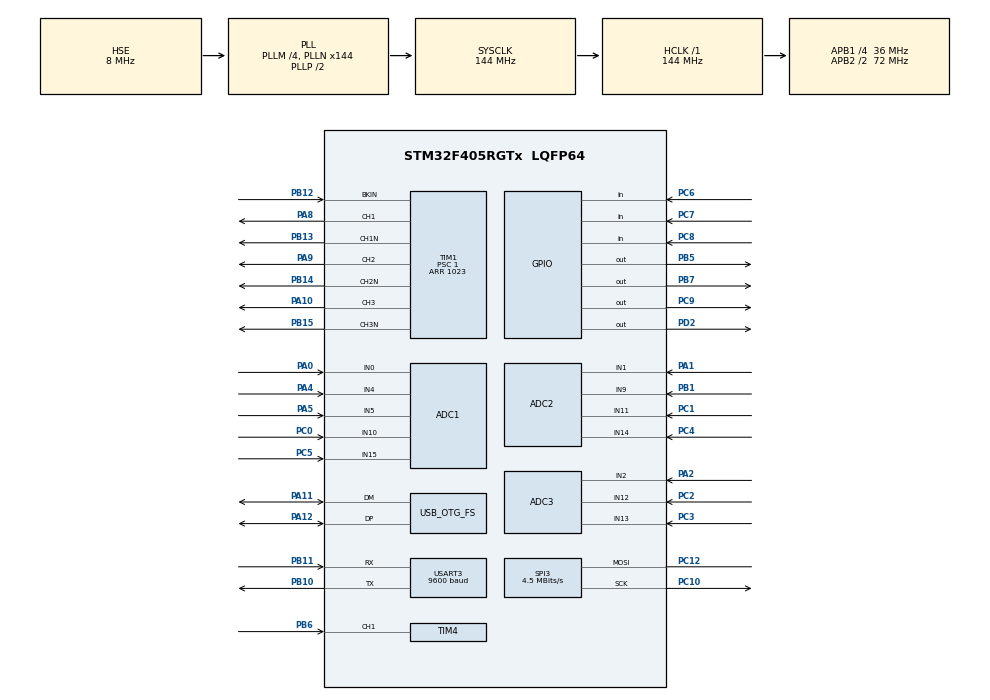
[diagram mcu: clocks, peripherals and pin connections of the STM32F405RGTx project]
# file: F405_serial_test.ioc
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ADC1.Channel-0\#ChannelRegularConversion=ADC_CHANNEL_10
ADC1.Channel-1\#ChannelInjectedConversion=ADC_CHANNEL_10
ADC1.Channel-2\#ChannelInjectedConversion=ADC_CHANNEL_0
ADC1.Channel-3\#ChannelInjectedConversion=ADC_CHANNEL_5
ADC1.Channel-4\#ChannelInjectedConversion=ADC_CHANNEL_4
ADC1.EOCSelection=ADC_EOC_SEQ_CONV
ADC1.EnableAnalogWatchDog=false
ADC1.ExternalTrigInjecConv=ADC_EXTERNALTRIGINJECCONV_T1_TRGO
ADC1.InjNumberOfConversion=4
ADC1.InjectedOffset-1\#ChannelInjectedConversion=0
ADC1.InjectedOffset-2\#ChannelInjectedConversion=0
ADC1.InjectedOffset-3\#ChannelInjectedConversion=0
ADC1.InjectedOffset-4\#ChannelInjectedConversion=0
ADC1.InjectedRank-1\#ChannelInjectedConversion=1
ADC1.InjectedRank-2\#ChannelInjectedConversion=2
ADC1.InjectedRank-3\#ChannelInjectedConversion=3
ADC1.InjectedRank-4\#ChannelInjectedConversion=4
ADC1.NbrOfConversion=1
ADC1.NbrOfConversionFlag=1
ADC1.Rank-0\#ChannelRegularConversion=1
ADC1.SamplingTime-0\#ChannelRegularConversion=ADC_SAMPLETIME_3CYCLES
ADC1.SamplingTime-1\#ChannelInjectedConversion=ADC_SAMPLETIME_15CYCLES
ADC1.SamplingTime-2\#ChannelInjectedConversion=ADC_SAMPLETIME_15CYCLES
ADC1.SamplingTime-3\#ChannelInjectedConversion=ADC_SAMPLETIME_15CYCLES
ADC1.SamplingTime-4\#ChannelInjectedConversion=ADC_SAMPLETIME_3CYCLES
ADC1.ScanConvMode=ENABLE
ADC1.master=1
ADC2.Channel-0\#ChannelRegularConversion=ADC_CHANNEL_11
ADC2.Channel-1\#ChannelInjectedConversion=ADC_CHANNEL_11
ADC2.Channel-2\#ChannelInjectedConversion=ADC_CHANNEL_14
ADC2.Channel-3\#ChannelInjectedConversion=ADC_CHANNEL_1
ADC2.Channel-4\#ChannelInjectedConversion=ADC_CHANNEL_9
ADC2.EOCSelection=ADC_EOC_SEQ_CONV
ADC2.ExternalTrigInjecConv=ADC_EXTERNALTRIGINJECCONV_T1_TRGO
ADC2.InjNumberOfConversion=4
ADC2.InjectedOffset-1\#ChannelInjectedConversion=0
ADC2.InjectedOffset-2\#ChannelInjectedConversion=0
ADC2.InjectedOffset-3\#ChannelInjectedConversion=0
ADC2.InjectedOffset-4\#ChannelInjectedConversion=0
ADC2.InjectedRank-1\#ChannelInjectedConversion=1
ADC2.InjectedRank-2\#ChannelInjectedConversion=2
ADC2.InjectedRank-3\#ChannelInjectedConversion=3
ADC2.InjectedRank-4\#ChannelInjectedConversion=4
ADC2.NbrOfConversionFlag=1
ADC2.Rank-0\#ChannelRegularConversion=1
ADC2.SamplingTime-0\#ChannelRegularConversion=ADC_SAMPLETIME_3CYCLES
ADC2.SamplingTime-1\#ChannelInjectedConversion=ADC_SAMPLETIME_15CYCLES
ADC2.SamplingTime-2\#ChannelInjectedConversion=ADC_SAMPLETIME_15CYCLES
ADC2.SamplingTime-3\#ChannelInjectedConversion=ADC_SAMPLETIME_15CYCLES
ADC2.SamplingTime-4\#ChannelInjectedConversion=ADC_SAMPLETIME_15CYCLES
ADC3.Channel-0\#ChannelRegularConversion=ADC_CHANNEL_12
ADC3.Channel-1\#ChannelInjectedConversion=ADC_CHANNEL_12
ADC3.Channel-2\#ChannelInjectedConversion=ADC_CHANNEL_13
ADC3.Channel-3\#ChannelInjectedConversion=ADC_CHANNEL_2
ADC3.EOCSelection=ADC_EOC_SEQ_CONV
ADC3.ExternalTrigInjecConv=ADC_EXTERNALTRIGINJECCONV_T1_TRGO
ADC3.InjNumberOfConversion=3
ADC3.InjectedOffset-1\#ChannelInjectedConversion=0
ADC3.InjectedOffset-2\#ChannelInjectedConversion=0
ADC3.InjectedOffset-3\#ChannelInjectedConversion=0
ADC3.InjectedRank-1\#ChannelInjectedConversion=1
ADC3.InjectedRank-2\#ChannelInjectedConversion=2
ADC3.InjectedRank-3\#ChannelInjectedConversion=3
ADC3.NbrOfConversionFlag=1
ADC3.Rank-0\#ChannelRegularConversion=1
ADC3.SamplingTime-0\#ChannelRegularConversion=ADC_SAMPLETIME_3CYCLES
ADC3.SamplingTime-1\#ChannelInjectedConversion=ADC_SAMPLETIME_15CYCLES
ADC3.SamplingTime-2\#ChannelInjectedConversion=ADC_SAMPLETIME_15CYCLES
ADC3.SamplingTime-3\#ChannelInjectedConversion=ADC_SAMPLETIME_15CYCLES
Dma.Request0=USART3_TX
Dma.USART3_TX.0.Direction=DMA_MEMORY_TO_PERIPH
Dma.USART3_TX.0.FIFOMode=DMA_FIFOMODE_DISABLE
Dma.USART3_TX.0.Instance=DMA1_Stream3
Dma.USART3_TX.0.MemDataAlignment=DMA_MDATAALIGN_BYTE
Dma.USART3_TX.0.MemInc=DMA_MINC_ENABLE
Dma.USART3_TX.0.Mode=DMA_NORMAL
Dma.USART3_TX.0.PeriphDataAlignment=DMA_PDATAALIGN_BYTE
Dma.USART3_TX.0.PeriphInc=DMA_PINC_DISABLE
Dma.USART3_TX.0.Priority=DMA_PRIORITY_LOW
Mcu.Family=STM32F4
Mcu.Name=STM32F405RGTx
Mcu.Package=LQFP64
NVIC.ADC_IRQn=true\:0\:0\:false\:false\:true\:true\:false\:true
NVIC.DMA1_Stream3_IRQn=true\:1\:0\:true\:false\:true\:false\:true\:true
NVIC.OTG_FS_IRQn=true\:3\:0\:true\:false\:true\:true\:true\:true
NVIC.PriorityGroup=NVIC_PRIORITYGROUP_4
NVIC.TIM1_UP_TIM10_IRQn=true\:1\:0\:true\:false\:true\:true\:false\:true
NVIC.TIM4_IRQn=true\:2\:0\:true\:false\:true\:true\:false\:true
NVIC.USART3_IRQn=true\:2\:0\:true\:false\:true\:true\:true\:true
PA0-WKUP.Signal=ADCx_IN0
PA1.Signal=ADCx_IN1
PA10.Signal=S_TIM1_CH3
PA11.Mode=Device_Only
PA11.Signal=USB_OTG_FS_DM
PA12.Mode=Device_Only
PA12.Signal=USB_OTG_FS_DP
PA13.Mode=Trace_Asynchronous_SW
PA13.Signal=SYS_JTMS-SWDIO
PA14.Mode=Trace_Asynchronous_SW
PA14.Signal=SYS_JTCK-SWCLK
PA2.Signal=ADCx_IN2
PA4.Signal=ADCx_IN4
PA5.Signal=ADCx_IN5
PA8.Signal=S_TIM1_CH1
PA9.Signal=S_TIM1_CH2
PB1.Signal=ADCx_IN9
PB10.Signal=SharedStack_PB10
PB10.Stacked=true
PB11.Signal=SharedStack_PB11
PB11.Stacked=true
PB12.Mode=Activate-Break-Input
PB12.Signal=TIM1_BKIN
PB13.Mode=PWM Generation1 CH1 CH1N
PB13.Signal=TIM1_CH1N
PB14.Mode=PWM Generation2 CH2 CH2N
PB14.Signal=TIM1_CH2N
PB15.Mode=PWM Generation3 CH3 CH3N
PB15.Signal=TIM1_CH3N
PB3.Mode=Trace_Asynchronous_SW
PB3.Signal=SYS_JTDO-SWO
PB5.Signal=GPIO_Output
PB6.Signal=S_TIM4_CH1
PB7.Signal=GPIO_Output
PC0.Signal=ADCx_IN10
PC1.Signal=ADCx_IN11
PC10.Mode=Simplex_Bidirectional_Master
PC10.Signal=SPI3_SCK
PC11.Signal=SPI3_MISO
PC12.Mode=Simplex_Bidirectional_Master
PC12.Signal=SPI3_MOSI
PC2.Signal=ADCx_IN12
PC3.Signal=ADCx_IN13
PC4.Signal=ADCx_IN14
PC5.Signal=ADCx_IN15
PC6.Signal=GPIO_Input
PC7.Signal=GPIO_Input
PC8.Signal=GPIO_Input
PC9.Signal=GPIO_Output
PD2.Signal=GPIO_Output
PH0-OSC_IN.Mode=HSE-External-Oscillator
PH0-OSC_IN.Signal=RCC_OSC_IN
PH1-OSC_OUT.Mode=HSE-External-Oscillator
PH1-OSC_OUT.Signal=RCC_OSC_OUT
ProjectManager.HeapSize=0x200
ProjectManager.StackSize=0x400
ProjectManager.TargetToolchain=STM32CubeIDE
RCC.48MHZClocksFreq_Value=48000000
RCC.AHBFreq_Value=144000000
RCC.APB1CLKDivider=RCC_HCLK_DIV4
RCC.APB1Freq_Value=36000000
RCC.APB1TimFreq_Value=72000000
RCC.APB2CLKDivider=RCC_HCLK_DIV2
RCC.APB2Freq_Value=72000000
RCC.APB2TimFreq_Value=144000000
RCC.CortexFreq_Value=144000000
RCC.HCLKFreq_Value=144000000
RCC.HSE_VALUE=8000000
RCC.HSI_VALUE=16000000
RCC.LSE_VALUE=32768
RCC.PLLM=4
RCC.PLLN=144
RCC.PLLQ=6
RCC.SYSCLKFreq_VALUE=144000000
RCC.SYSCLKSource=RCC_SYSCLKSOURCE_PLLCLK
RCC.VCOOutputFreq_Value=288000000
SH.ADCx_IN0.0=ADC1_IN0,IN0
SH.ADCx_IN1.0=ADC2_IN1,IN1
SH.ADCx_IN10.0=ADC1_IN10,IN10
SH.ADCx_IN11.0=ADC2_IN11,IN11
SH.ADCx_IN12.0=ADC3_IN12,IN12
SH.ADCx_IN13.0=ADC3_IN13,IN13
SH.ADCx_IN14.0=ADC2_IN14,IN14
SH.ADCx_IN15.0=ADC1_IN15,IN15
SH.ADCx_IN2.0=ADC3_IN2,IN2
SH.ADCx_IN4.0=ADC1_IN4,IN4
SH.ADCx_IN5.0=ADC1_IN5,IN5
SH.ADCx_IN9.0=ADC2_IN9,IN9
SH.S_TIM1_CH1.0=TIM1_CH1,PWM Generation1 CH1 CH1N
SH.S_TIM1_CH2.0=TIM1_CH2,PWM Generation2 CH2 CH2N
SH.S_TIM1_CH3.0=TIM1_CH3,PWM Generation3 CH3 CH3N
SH.S_TIM4_CH1.0=TIM4_CH1,Input_Capture1_from_TI1
SH.S_TIM4_CH1.1=TIM4_CH1,Input_Capture2_from_TI1
SH.S_TIM4_CH1.2=TIM4_CH1,TriggerSource_TI1FP1
SH.SharedStack_PB10.0=USART3_TX,Asynchronous
SH.SharedStack_PB10.1=I2C2_SCL
SH.SharedStack_PB11.0=USART3_RX,Asynchronous
SH.SharedStack_PB11.1=I2C2_SDA
SPI3.BaudRatePrescaler=SPI_BAUDRATEPRESCALER_8
SPI3.CLKPhase=SPI_PHASE_2EDGE
SPI3.CalculateBaudRate=4.5 MBits/s
SPI3.DataSize=SPI_DATASIZE_16BIT
SPI3.Direction=SPI_DIRECTION_1LINE
SPI3.Mode=SPI_MODE_MASTER
SPI3.VirtualType=VM_MASTER
TIM1.BreakPolarity=TIM_BREAKPOLARITY_LOW
TIM1.Channel-PWM\ Generation1\ CH1\ CH1N=TIM_CHANNEL_1
TIM1.Channel-PWM\ Generation2\ CH2\ CH2N=TIM_CHANNEL_2
TIM1.Channel-PWM\ Generation3\ CH3\ CH3N=TIM_CHANNEL_3
TIM1.Channel-PWM\ Generation4\ No\ Output=TIM_CHANNEL_4
TIM1.CounterMode=TIM_COUNTERMODE_CENTERALIGNED1
TIM1.DeadTime=50
TIM1.OffStateIDLEMode=TIM_OSSI_ENABLE
TIM1.OffStateRunMode=TIM_OSSR_ENABLE
TIM1.Period=1023
TIM1.Prescaler=1
TIM1.Pulse-PWM\ Generation1\ CH1\ CH1N=512
TIM1.Pulse-PWM\ Generation2\ CH2\ CH2N=512
TIM1.Pulse-PWM\ Generation3\ CH3\ CH3N=512
TIM1.TIM_MasterOutputTrigger=TIM_TRGO_OC4REF
TIM4.Channel-Input_Capture1_from_TI1=TIM_CHANNEL_1
TIM4.Channel-Input_Capture2_from_TI1=TIM_CHANNEL_2
TIM4.ICPolarity_CH2=TIM_INPUTCHANNELPOLARITY_FALLING
TIM4.Period=50000
TIM4.Prescaler=71
USART3.BaudRate=9600
USART3.VirtualMode=VM_ASYNC
USB_DEVICE.APP_RX_DATA_SIZE-CDC_FS=1000
USB_DEVICE.APP_TX_DATA_SIZE-CDC_FS=1000
USB_DEVICE.CLASS_NAME_FS=CDC
USB_DEVICE.VirtualMode-CDC_FS=Cdc
USB_DEVICE.VirtualModeFS=Cdc_FS
USB_OTG_FS.VirtualMode=Device_Only
VP_TIM1_VS_no_output4.Mode=PWM Generation4 No Output
VP_TIM4_VS_ControllerModeReset.Mode=Reset Mode
VP_TIM7_VS_ClockSourceINT.Mode=Enable_Timer
VP_USB_DEVICE_VS_USB_DEVICE_CDC_FS.Mode=CDC_FS
board=custom

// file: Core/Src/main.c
/* USER CODE BEGIN Header */
/**
  ******************************************************************************
  * @file           : main.c
  * @brief          : Main program body
  ******************************************************************************
  * @attention
  *
  * Copyright (c) 2022 STMicroelectronics.
  * All rights reserved.
  *
  * This software is licensed under terms that can be found in the LICENSE file
  * in the root directory of this software component.
  * If no LICENSE file comes with this software, it is provided AS-IS.
  *
  ******************************************************************************
  */
/* USER CODE END Header */
#include "main.h"
#include "usb_device.h"
#include <stdbool.h>

ADC_HandleTypeDef hadc1;
ADC_HandleTypeDef hadc2;
ADC_HandleTypeDef hadc3;

SPI_HandleTypeDef hspi3;

TIM_HandleTypeDef htim1;
TIM_HandleTypeDef htim4;
TIM_HandleTypeDef htim7;

UART_HandleTypeDef huart3;
DMA_HandleTypeDef hdma_usart3_tx;

void SystemClock_Config(void);
static void MX_GPIO_Init(void);
static void MX_DMA_Init(void);
static void MX_ADC1_Init(void);
static void MX_ADC2_Init(void);
static void MX_ADC3_Init(void);
static void MX_TIM1_Init(void);
static void MX_TIM4_Init(void);
static void MX_USART3_UART_Init(void);
static void MX_TIM7_Init(void);
static void MX_SPI3_Init(void);

/* USER CODE BEGIN 0 */
uint32_t milliStart;
uint32_t milliCurrent;
uint32_t milliDelta;
bool milliReset = true;

/* USER CODE END 0 */

int main(void)
{

  /* MCU Configuration--------------------------------------------------------*/

  /* Reset of all peripherals, Initializes the Flash interface and the Systick. */
  HAL_Init();

  /* Configure the system clock */
  SystemClock_Config();

  /* Initialize all configured peripherals */
  MX_GPIO_Init();
  MX_DMA_Init();
  MX_ADC1_Init();
  MX_ADC2_Init();
  MX_ADC3_Init();
  MX_TIM1_Init();
  MX_TIM4_Init();
  MX_USART3_UART_Init();
  MX_TIM7_Init();
  MX_SPI3_Init();
  MX_USB_DEVICE_Init();

  /* Infinite loop */
  while (1)
  {
	  HAL_GPIO_TogglePin (GPIOC, GPIO_PIN_9);
	  HAL_Delay (120);
	  char transmit_buffer[100];
	  int sizebuff;
	  milliCurrent = HAL_GetTick();
	  if (milliReset) {
		  // some day it would be cool if the user could reset this
		  // doesnt work yet
		  milliStart = milliCurrent;
	  }
	  milliReset = false;

	  sizebuff = sprintf(transmit_buffer,"{\"mS\":%lu, \"amps\":%d, \"volts\":%d}\r\n", (milliCurrent - milliStart), rand() %  200, rand() % 200);
	  HAL_UART_Transmit_DMA(&huart3, transmit_buffer, sizebuff);
  }
}

void SystemClock_Config(void)
{
  RCC_OscInitTypeDef RCC_OscInitStruct = {0};
  RCC_ClkInitTypeDef RCC_ClkInitStruct = {0};

  /** Configure the main internal regulator output voltage
  */
  __HAL_RCC_PWR_CLK_ENABLE();
  __HAL_PWR_VOLTAGESCALING_CONFIG(PWR_REGULATOR_VOLTAGE_SCALE1);

  /** Initializes the RCC Oscillators according to the specified parameters
  * in the RCC_OscInitTypeDef structure.
  */
  RCC_OscInitStruct.OscillatorType = RCC_OSCILLATORTYPE_HSE;
  RCC_OscInitStruct.HSEState = RCC_HSE_ON;
  RCC_OscInitStruct.PLL.PLLState = RCC_PLL_ON;
  RCC_OscInitStruct.PLL.PLLSource = RCC_PLLSOURCE_HSE;
  RCC_OscInitStruct.PLL.PLLM = 4;
  RCC_OscInitStruct.PLL.PLLN = 144;
  RCC_OscInitStruct.PLL.PLLP = RCC_PLLP_DIV2;
  RCC_OscInitStruct.PLL.PLLQ = 6;
  if (HAL_RCC_OscConfig(&RCC_OscInitStruct) != HAL_OK)
  {
    Error_Handler();
  }

  /** Initializes the CPU, AHB and APB buses clocks
  */
  RCC_ClkInitStruct.ClockType = RCC_CLOCKTYPE_HCLK|RCC_CLOCKTYPE_SYSCLK
                              |RCC_CLOCKTYPE_PCLK1|RCC_CLOCKTYPE_PCLK2;
  RCC_ClkInitStruct.SYSCLKSource = RCC_SYSCLKSOURCE_PLLCLK;
  RCC_ClkInitStruct.AHBCLKDivider = RCC_SYSCLK_DIV1;
  RCC_ClkInitStruct.APB1CLKDivider = RCC_HCLK_DIV4;
  RCC_ClkInitStruct.APB2CLKDivider = RCC_HCLK_DIV2;

  if (HAL_RCC_ClockConfig(&RCC_ClkInitStruct, FLASH_LATENCY_4) != HAL_OK)
  {
    Error_Handler();
  }
}

static void MX_ADC1_Init(void)
{

  ADC_ChannelConfTypeDef sConfig = {0};
  ADC_InjectionConfTypeDef sConfigInjected = {0};

  /** Configure the global features of the ADC (Clock, Resolution, Data Alignment and number of conversion)
  */
  hadc1.Instance = ADC1;
  hadc1.Init.ClockPrescaler = ADC_CLOCK_SYNC_PCLK_DIV2;
  hadc1.Init.Resolution = ADC_RESOLUTION_12B;
  hadc1.Init.ScanConvMode = ENABLE;
  hadc1.Init.ContinuousConvMode = DISABLE;
  hadc1.Init.DiscontinuousConvMode = DISABLE;
  hadc1.Init.ExternalTrigConvEdge = ADC_EXTERNALTRIGCONVEDGE_NONE;
  hadc1.Init.ExternalTrigConv = ADC_SOFTWARE_START;
  hadc1.Init.DataAlign = ADC_DATAALIGN_RIGHT;
  hadc1.Init.NbrOfConversion = 1;
  hadc1.Init.DMAContinuousRequests = DISABLE;
  hadc1.Init.EOCSelection = ADC_EOC_SEQ_CONV;
  if (HAL_ADC_Init(&hadc1) != HAL_OK)
  {
    Error_Handler();
  }

  /** Configure for the selected ADC regular channel its corresponding rank in the sequencer and its sample time.
  */
  sConfig.Channel = ADC_CHANNEL_10;
  sConfig.Rank = 1;
  sConfig.SamplingTime = ADC_SAMPLETIME_3CYCLES;
  if (HAL_ADC_ConfigChannel(&hadc1, &sConfig) != HAL_OK)
  {
    Error_Handler();
  }

  /** Configures for the selected ADC injected channel its corresponding rank in the sequencer and its sample time
  */
  sConfigInjected.InjectedChannel = ADC_CHANNEL_10;
  sConfigInjected.InjectedRank = 1;
  sConfigInjected.InjectedNbrOfConversion = 4;
  sConfigInjected.InjectedSamplingTime = ADC_SAMPLETIME_15CYCLES;
  sConfigInjected.ExternalTrigInjecConvEdge = ADC_EXTERNALTRIGINJECCONVEDGE_RISING;
  sConfigInjected.ExternalTrigInjecConv = ADC_EXTERNALTRIGINJECCONV_T1_TRGO;
  sConfigInjected.AutoInjectedConv = DISABLE;
  sConfigInjected.InjectedDiscontinuousConvMode = DISABLE;
  sConfigInjected.InjectedOffset = 0;
  if (HAL_ADCEx_InjectedConfigChannel(&hadc1, &sConfigInjected) != HAL_OK)
  {
    Error_Handler();
  }

  /** Configures for the selected ADC injected channel its corresponding rank in the sequencer and its sample time
  */
  sConfigInjected.InjectedChannel = ADC_CHANNEL_0;
  sConfigInjected.InjectedRank = 2;
  if (HAL_ADCEx_InjectedConfigChannel(&hadc1, &sConfigInjected) != HAL_OK)
  {
    Error_Handler();
  }

  /** Configures for the selected ADC injected channel its corresponding rank in the sequencer and its sample time
  */
  sConfigInjected.InjectedChannel = ADC_CHANNEL_5;
  sConfigInjected.InjectedRank = 3;
  if (HAL_ADCEx_InjectedConfigChannel(&hadc1, &sConfigInjected) != HAL_OK)
  {
    Error_Handler();
  }

  /** Configures for the selected ADC injected channel its corresponding rank in the sequencer and its sample time
  */
  sConfigInjected.InjectedChannel = ADC_CHANNEL_4;
  sConfigInjected.InjectedRank = 4;
  sConfigInjected.InjectedSamplingTime = ADC_SAMPLETIME_3CYCLES;
  if (HAL_ADCEx_InjectedConfigChannel(&hadc1, &sConfigInjected) != HAL_OK)
  {
    Error_Handler();
  }

}

static void MX_ADC2_Init(void)
{

  ADC_ChannelConfTypeDef sConfig = {0};
  ADC_InjectionConfTypeDef sConfigInjected = {0};

  /** Configure the global features of the ADC (Clock, Resolution, Data Alignment and number of conversion)
  */
  hadc2.Instance = ADC2;
  hadc2.Init.ClockPrescaler = ADC_CLOCK_SYNC_PCLK_DIV2;
  hadc2.Init.Resolution = ADC_RESOLUTION_12B;
  hadc2.Init.ScanConvMode = ENABLE;
  hadc2.Init.ContinuousConvMode = DISABLE;
  hadc2.Init.DiscontinuousConvMode = DISABLE;
  hadc2.Init.ExternalTrigConvEdge = ADC_EXTERNALTRIGCONVEDGE_NONE;
  hadc2.Init.ExternalTrigConv = ADC_SOFTWARE_START;
  hadc2.Init.DataAlign = ADC_DATAALIGN_RIGHT;
  hadc2.Init.NbrOfConversion = 1;
  hadc2.Init.DMAContinuousRequests = DISABLE;
  hadc2.Init.EOCSelection = ADC_EOC_SEQ_CONV;
  if (HAL_ADC_Init(&hadc2) != HAL_OK)
  {
    Error_Handler();
  }

  /** Configure for the selected ADC regular channel its corresponding rank in the sequencer and its sample time.
  */
  sConfig.Channel = ADC_CHANNEL_11;
  sConfig.Rank = 1;
  sConfig.SamplingTime = ADC_SAMPLETIME_3CYCLES;
  if (HAL_ADC_ConfigChannel(&hadc2, &sConfig) != HAL_OK)
  {
    Error_Handler();
  }

  /** Configures for the selected ADC injected channel its corresponding rank in the sequencer and its sample time
  */
  sConfigInjected.InjectedChannel = ADC_CHANNEL_11;
  sConfigInjected.InjectedRank = 1;
  sConfigInjected.InjectedNbrOfConversion = 4;
  sConfigInjected.InjectedSamplingTime = ADC_SAMPLETIME_15CYCLES;
  sConfigInjected.ExternalTrigInjecConvEdge = ADC_EXTERNALTRIGINJECCONVEDGE_RISING;
  sConfigInjected.ExternalTrigInjecConv = ADC_EXTERNALTRIGINJECCONV_T1_TRGO;
  sConfigInjected.AutoInjectedConv = DISABLE;
  sConfigInjected.InjectedDiscontinuousConvMode = DISABLE;
  sConfigInjected.InjectedOffset = 0;
  if (HAL_ADCEx_InjectedConfigChannel(&hadc2, &sConfigInjected) != HAL_OK)
  {
    Error_Handler();
  }

  /** Configures for the selected ADC injected channel its corresponding rank in the sequencer and its sample time
  */
  sConfigInjected.InjectedChannel = ADC_CHANNEL_14;
  sConfigInjected.InjectedRank = 2;
  if (HAL_ADCEx_InjectedConfigChannel(&hadc2, &sConfigInjected) != HAL_OK)
  {
    Error_Handler();
  }

  /** Configures for the selected ADC injected channel its corresponding rank in the sequencer and its sample time
  */
  sConfigInjected.InjectedChannel = ADC_CHANNEL_1;
  sConfigInjected.InjectedRank = 3;
  if (HAL_ADCEx_InjectedConfigChannel(&hadc2, &sConfigInjected) != HAL_OK)
  {
    Error_Handler();
  }

  /** Configures for the selected ADC injected channel its corresponding rank in the sequencer and its sample time
  */
  sConfigInjected.InjectedChannel = ADC_CHANNEL_9;
  sConfigInjected.InjectedRank = 4;
  if (HAL_ADCEx_InjectedConfigChannel(&hadc2, &sConfigInjected) != HAL_OK)
  {
    Error_Handler();
  }

}

static void MX_ADC3_Init(void)
{

  ADC_ChannelConfTypeDef sConfig = {0};
  ADC_InjectionConfTypeDef sConfigInjected = {0};

  /** Configure the global features of the ADC (Clock, Resolution, Data Alignment and number of conversion)
  */
  hadc3.Instance = ADC3;
  hadc3.Init.ClockPrescaler = ADC_CLOCK_SYNC_PCLK_DIV2;
  hadc3.Init.Resolution = ADC_RESOLUTION_12B;
  hadc3.Init.ScanConvMode = ENABLE;
  hadc3.Init.ContinuousConvMode = DISABLE;
  hadc3.Init.DiscontinuousConvMode = DISABLE;
  hadc3.Init.ExternalTrigConvEdge = ADC_EXTERNALTRIGCONVEDGE_NONE;
  hadc3.Init.ExternalTrigConv = ADC_SOFTWARE_START;
  hadc3.Init.DataAlign = ADC_DATAALIGN_RIGHT;
  hadc3.Init.NbrOfConversion = 1;
  hadc3.Init.DMAContinuousRequests = DISABLE;
  hadc3.Init.EOCSelection = ADC_EOC_SEQ_CONV;
  if (HAL_ADC_Init(&hadc3) != HAL_OK)
  {
    Error_Handler();
  }

  /** Configure for the selected ADC regular channel its corresponding rank in the sequencer and its sample time.
  */
  sConfig.Channel = ADC_CHANNEL_12;
  sConfig.Rank = 1;
  sConfig.SamplingTime = ADC_SAMPLETIME_3CYCLES;
  if (HAL_ADC_ConfigChannel(&hadc3, &sConfig) != HAL_OK)
  {
    Error_Handler();
  }

  /** Configures for the selected ADC injected channel its corresponding rank in the sequencer and its sample time
  */
  sConfigInjected.InjectedChannel = ADC_CHANNEL_12;
  sConfigInjected.InjectedRank = 1;
  sConfigInjected.InjectedNbrOfConversion = 3;
  sConfigInjected.InjectedSamplingTime = ADC_SAMPLETIME_15CYCLES;
  sConfigInjected.ExternalTrigInjecConvEdge = ADC_EXTERNALTRIGINJECCONVEDGE_RISING;
  sConfigInjected.ExternalTrigInjecConv = ADC_EXTERNALTRIGINJECCONV_T1_TRGO;
  sConfigInjected.AutoInjectedConv = DISABLE;
  sConfigInjected.InjectedDiscontinuousConvMode = DISABLE;
  sConfigInjected.InjectedOffset = 0;
  if (HAL_ADCEx_InjectedConfigChannel(&hadc3, &sConfigInjected) != HAL_OK)
  {
    Error_Handler();
  }

  /** Configures for the selected ADC injected channel its corresponding rank in the sequencer and its sample time
  */
  sConfigInjected.InjectedChannel = ADC_CHANNEL_13;
  sConfigInjected.InjectedRank = 2;
  if (HAL_ADCEx_InjectedConfigChannel(&hadc3, &sConfigInjected) != HAL_OK)
  {
    Error_Handler();
  }

  /** Configures for the selected ADC injected channel its corresponding rank in the sequencer and its sample time
  */
  sConfigInjected.InjectedChannel = ADC_CHANNEL_2;
  sConfigInjected.InjectedRank = 3;
  if (HAL_ADCEx_InjectedConfigChannel(&hadc3, &sConfigInjected) != HAL_OK)
  {
    Error_Handler();
  }

}

static void MX_SPI3_Init(void)
{

  /* SPI3 parameter configuration*/
  hspi3.Instance = SPI3;
  hspi3.Init.Mode = SPI_MODE_MASTER;
  hspi3.Init.Direction = SPI_DIRECTION_1LINE;
  hspi3.Init.DataSize = SPI_DATASIZE_16BIT;
  hspi3.Init.CLKPolarity = SPI_POLARITY_LOW;
  hspi3.Init.CLKPhase = SPI_PHASE_2EDGE;
  hspi3.Init.NSS = SPI_NSS_SOFT;
  hspi3.Init.BaudRatePrescaler = SPI_BAUDRATEPRESCALER_8;
  hspi3.Init.FirstBit = SPI_FIRSTBIT_MSB;
  hspi3.Init.TIMode = SPI_TIMODE_DISABLE;
  hspi3.Init.CRCCalculation = SPI_CRCCALCULATION_DISABLE;
  hspi3.Init.CRCPolynomial = 10;
  if (HAL_SPI_Init(&hspi3) != HAL_OK)
  {
    Error_Handler();
  }

}

static void MX_TIM1_Init(void)
{

  TIM_MasterConfigTypeDef sMasterConfig = {0};
  TIM_OC_InitTypeDef sConfigOC = {0};
  TIM_BreakDeadTimeConfigTypeDef sBreakDeadTimeConfig = {0};

  htim1.Instance = TIM1;
  htim1.Init.Prescaler = 1;
  htim1.Init.CounterMode = TIM_COUNTERMODE_CENTERALIGNED1;
  htim1.Init.Period = 1023;
  htim1.Init.ClockDivision = TIM_CLOCKDIVISION_DIV1;
  htim1.Init.RepetitionCounter = 0;
  htim1.Init.AutoReloadPreload = TIM_AUTORELOAD_PRELOAD_DISABLE;
  if (HAL_TIM_PWM_Init(&htim1) != HAL_OK)
  {
    Error_Handler();
  }
  sMasterConfig.MasterOutputTrigger = TIM_TRGO_OC4REF;
  sMasterConfig.MasterSlaveMode = TIM_MASTERSLAVEMODE_DISABLE;
  if (HAL_TIMEx_MasterConfigSynchronization(&htim1, &sMasterConfig) != HAL_OK)
  {
    Error_Handler();
  }
  sConfigOC.OCMode = TIM_OCMODE_PWM1;
  sConfigOC.Pulse = 512;
  sConfigOC.OCPolarity = TIM_OCPOLARITY_HIGH;
  sConfigOC.OCNPolarity = TIM_OCNPOLARITY_HIGH;
  sConfigOC.OCFastMode = TIM_OCFAST_DISABLE;
  sConfigOC.OCIdleState = TIM_OCIDLESTATE_RESET;
  sConfigOC.OCNIdleState = TIM_OCNIDLESTATE_RESET;
  if (HAL_TIM_PWM_ConfigChannel(&htim1, &sConfigOC, TIM_CHANNEL_1) != HAL_OK)
  {
    Error_Handler();
  }
  if (HAL_TIM_PWM_ConfigChannel(&htim1, &sConfigOC, TIM_CHANNEL_2) != HAL_OK)
  {
    Error_Handler();
  }
  if (HAL_TIM_PWM_ConfigChannel(&htim1, &sConfigOC, TIM_CHANNEL_3) != HAL_OK)
  {
    Error_Handler();
  }
  sConfigOC.Pulse = 0;
  if (HAL_TIM_PWM_ConfigChannel(&htim1, &sConfigOC, TIM_CHANNEL_4) != HAL_OK)
  {
    Error_Handler();
  }
  sBreakDeadTimeConfig.OffStateRunMode = TIM_OSSR_ENABLE;
  sBreakDeadTimeConfig.OffStateIDLEMode = TIM_OSSI_ENABLE;
  sBreakDeadTimeConfig.LockLevel = TIM_LOCKLEVEL_OFF;
  sBreakDeadTimeConfig.DeadTime = 50;
  sBreakDeadTimeConfig.BreakState = TIM_BREAK_ENABLE;
  sBreakDeadTimeConfig.BreakPolarity = TIM_BREAKPOLARITY_LOW;
  sBreakDeadTimeConfig.AutomaticOutput = TIM_AUTOMATICOUTPUT_DISABLE;
  if (HAL_TIMEx_ConfigBreakDeadTime(&htim1, &sBreakDeadTimeConfig) != HAL_OK)
  {
    Error_Handler();
  }
  HAL_TIM_MspPostInit(&htim1);

}

static void MX_TIM4_Init(void)
{

  TIM_SlaveConfigTypeDef sSlaveConfig = {0};
  TIM_MasterConfigTypeDef sMasterConfig = {0};
  TIM_IC_InitTypeDef sConfigIC = {0};

  htim4.Instance = TIM4;
  htim4.Init.Prescaler = 71;
  htim4.Init.CounterMode = TIM_COUNTERMODE_UP;
  htim4.Init.Period = 50000;
  htim4.Init.ClockDivision = TIM_CLOCKDIVISION_DIV1;
  htim4.Init.AutoReloadPreload = TIM_AUTORELOAD_PRELOAD_DISABLE;
  if (HAL_TIM_Base_Init(&htim4) != HAL_OK)
  {
    Error_Handler();
  }
  if (HAL_TIM_IC_Init(&htim4) != HAL_OK)
  {
    Error_Handler();
  }
  sSlaveConfig.SlaveMode = TIM_SLAVEMODE_RESET;
  sSlaveConfig.InputTrigger = TIM_TS_TI1FP1;
  sSlaveConfig.TriggerPolarity = TIM_INPUTCHANNELPOLARITY_RISING;
  sSlaveConfig.TriggerFilter = 0;
  if (HAL_TIM_SlaveConfigSynchro(&htim4, &sSlaveConfig) != HAL_OK)
  {
    Error_Handler();
  }
  sMasterConfig.MasterOutputTrigger = TIM_TRGO_RESET;
  sMasterConfig.MasterSlaveMode = TIM_MASTERSLAVEMODE_DISABLE;
  if (HAL_TIMEx_MasterConfigSynchronization(&htim4, &sMasterConfig) != HAL_OK)
  {
    Error_Handler();
  }
  sConfigIC.ICPolarity = TIM_INPUTCHANNELPOLARITY_RISING;
  sConfigIC.ICSelection = TIM_ICSELECTION_DIRECTTI;
  sConfigIC.ICPrescaler = TIM_ICPSC_DIV1;
  sConfigIC.ICFilter = 0;
  if (HAL_TIM_IC_ConfigChannel(&htim4, &sConfigIC, TIM_CHANNEL_1) != HAL_OK)
  {
    Error_Handler();
  }
  sConfigIC.ICPolarity = TIM_INPUTCHANNELPOLARITY_FALLING;
  sConfigIC.ICSelection = TIM_ICSELECTION_INDIRECTTI;
  if (HAL_TIM_IC_ConfigChannel(&htim4, &sConfigIC, TIM_CHANNEL_2) != HAL_OK)
  {
    Error_Handler();
  }

}

static void MX_TIM7_Init(void)
{

  TIM_MasterConfigTypeDef sMasterConfig = {0};

  htim7.Instance = TIM7;
  htim7.Init.Prescaler = 0;
  htim7.Init.CounterMode = TIM_COUNTERMODE_UP;
  htim7.Init.Period = 65535;
  htim7.Init.AutoReloadPreload = TIM_AUTORELOAD_PRELOAD_DISABLE;
  if (HAL_TIM_Base_Init(&htim7) != HAL_OK)
  {
    Error_Handler();
  }
  sMasterConfig.MasterOutputTrigger = TIM_TRGO_RESET;
  sMasterConfig.MasterSlaveMode = TIM_MASTERSLAVEMODE_DISABLE;
  if (HAL_TIMEx_MasterConfigSynchronization(&htim7, &sMasterConfig) != HAL_OK)
  {
    Error_Handler();
  }

}

static void MX_USART3_UART_Init(void)
{

  huart3.Instance = USART3;
  huart3.Init.BaudRate = 115200;
  huart3.Init.WordLength = UART_WORDLENGTH_8B;
  huart3.Init.StopBits = UART_STOPBITS_1;
  huart3.Init.Parity = UART_PARITY_NONE;
  huart3.Init.Mode = UART_MODE_TX_RX;
  huart3.Init.HwFlowCtl = UART_HWCONTROL_NONE;
  huart3.Init.OverSampling = UART_OVERSAMPLING_16;
  if (HAL_UART_Init(&huart3) != HAL_OK)
  {
    Error_Handler();
  }

}

static void MX_DMA_Init(void)
{

  /* DMA controller clock enable */
  __HAL_RCC_DMA1_CLK_ENABLE();

  /* DMA interrupt init */
  /* DMA1_Stream3_IRQn interrupt configuration */
  HAL_NVIC_SetPriority(DMA1_Stream3_IRQn, 1, 0);
  HAL_NVIC_EnableIRQ(DMA1_Stream3_IRQn);

}

static void MX_GPIO_Init(void)
{
  GPIO_InitTypeDef GPIO_InitStruct = {0};

  /* GPIO Ports Clock Enable */
  __HAL_RCC_GPIOH_CLK_ENABLE();
  __HAL_RCC_GPIOC_CLK_ENABLE();
  __HAL_RCC_GPIOA_CLK_ENABLE();
  __HAL_RCC_GPIOB_CLK_ENABLE();
  __HAL_RCC_GPIOD_CLK_ENABLE();

  /*Configure GPIO pin Output Level */
  HAL_GPIO_WritePin(GPIOC, GPIO_PIN_9, GPIO_PIN_RESET);

  /*Configure GPIO pin Output Level */
  HAL_GPIO_WritePin(GPIOD, GPIO_PIN_2, GPIO_PIN_RESET);

  /*Configure GPIO pin Output Level */
  HAL_GPIO_WritePin(GPIOB, GPIO_PIN_5|GPIO_PIN_7, GPIO_PIN_RESET);

  /*Configure GPIO pins : PC6 PC7 PC8 */
  GPIO_InitStruct.Pin = GPIO_PIN_6|GPIO_PIN_7|GPIO_PIN_8;
  GPIO_InitStruct.Mode = GPIO_MODE_INPUT;
  GPIO_InitStruct.Pull = GPIO_NOPULL;
  HAL_GPIO_Init(GPIOC, &GPIO_InitStruct);

  /*Configure GPIO pin : PC9 */
  GPIO_InitStruct.Pin = GPIO_PIN_9;
  GPIO_InitStruct.Mode = GPIO_MODE_OUTPUT_PP;
  GPIO_InitStruct.Pull = GPIO_NOPULL;
  GPIO_InitStruct.Speed = GPIO_SPEED_FREQ_LOW;
  HAL_GPIO_Init(GPIOC, &GPIO_InitStruct);

  /*Configure GPIO pin : PD2 */
  GPIO_InitStruct.Pin = GPIO_PIN_2;
  GPIO_InitStruct.Mode = GPIO_MODE_OUTPUT_PP;
  GPIO_InitStruct.Pull = GPIO_NOPULL;
  GPIO_InitStruct.Speed = GPIO_SPEED_FREQ_LOW;
  HAL_GPIO_Init(GPIOD, &GPIO_InitStruct);

  /*Configure GPIO pins : PB5 PB7 */
  GPIO_InitStruct.Pin = GPIO_PIN_5|GPIO_PIN_7;
  GPIO_InitStruct.Mode = GPIO_MODE_OUTPUT_PP;
  GPIO_InitStruct.Pull = GPIO_NOPULL;
  GPIO_InitStruct.Speed = GPIO_SPEED_FREQ_LOW;
  HAL_GPIO_Init(GPIOB, &GPIO_InitStruct);

}

void Error_Handler(void)
{
  __disable_irq();
  while (1)
  {
  }
}
